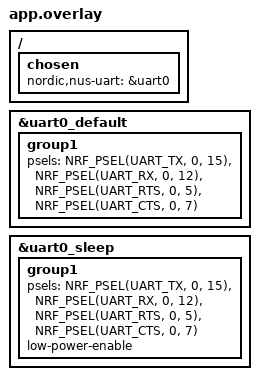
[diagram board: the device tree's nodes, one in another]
/*
 * Copyright (c) 2022 Nordic Semiconductor ASA
 *
 * SPDX-License-Identifier: LicenseRef-Nordic-5-Clause
 */

/ {
	chosen {
		nordic,nus-uart = &uart0;
	};
};

&uart0_default {
	group1 {
		psels = <NRF_PSEL(UART_TX, 0, 15)>,
				<NRF_PSEL(UART_RX, 0, 12)>,
				<NRF_PSEL(UART_RTS, 0, 5)>,
				<NRF_PSEL(UART_CTS, 0, 7)>;
	};
};

&uart0_sleep{
	group1 {
		psels = <NRF_PSEL(UART_TX, 0, 15)>,
				<NRF_PSEL(UART_RX, 0, 12)>,
				<NRF_PSEL(UART_RTS, 0, 5)>,
				<NRF_PSEL(UART_CTS, 0, 7)>;
		low-power-enable;
	};
};
